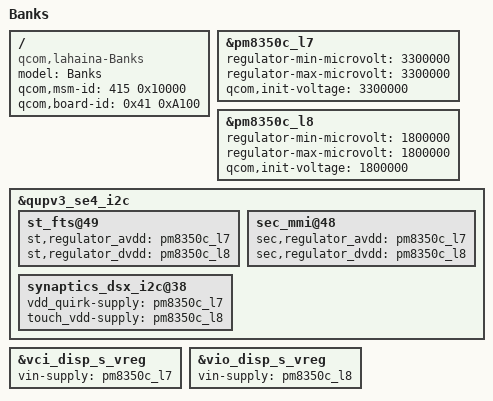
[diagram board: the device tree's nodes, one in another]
/* Copyright (c) 2020, The Linux Foundation. All rights reserved.
 *
 * This program is free software; you can redistribute it and/or modify
 * it under the terms of the GNU General Public License version 2 and
 * only version 2 as published by the Free Software Foundation.
 *
 * This program is distributed in the hope that it will be useful,
 * but WITHOUT ANY WARRANTY; without even the implied warranty of
 * MERCHANTABILITY or FITNESS FOR A PARTICULAR PURPOSE.  See the
 * GNU General Public License for more details.
 */

/dts-v1/;
/plugin/;

#include "lahaina-banks-common-overlay.dtsi"

/ {
	model = "Banks";
	compatible = "qcom,lahaina-Banks", "qcom,lahaina-moto", "qcom,lahaina";
	qcom,msm-id = <415 0x10000>;
	qcom,board-id = <0x41 0xA100>;
};

&pm8350c_l7 {
        regulator-min-microvolt = <3300000>;
        regulator-max-microvolt = <3300000>;
        qcom,init-voltage = <3300000>;
};

&pm8350c_l8 {
        regulator-min-microvolt = <1800000>;
        regulator-max-microvolt = <1800000>;
        qcom,init-voltage = <1800000>;
};

&qupv3_se4_i2c {
	st_fts@49 {
		st,regulator_avdd = "pm8350c_l7";
		st,regulator_dvdd = "pm8350c_l8";
	};

	sec_mmi@48 {
		status = "ok";
		sec,regulator_avdd = "pm8350c_l7";
		sec,regulator_dvdd = "pm8350c_l8";
	};

	synaptics_dsx_i2c@38 {
		vdd_quirk-supply = <&pm8350c_l7>;
		touch_vdd-supply= <&pm8350c_l8>;
	};
};

&vci_disp_s_vreg {
	vin-supply = <&pm8350c_l7>;
};

&vio_disp_s_vreg {
	vin-supply = <&pm8350c_l8>;
};
